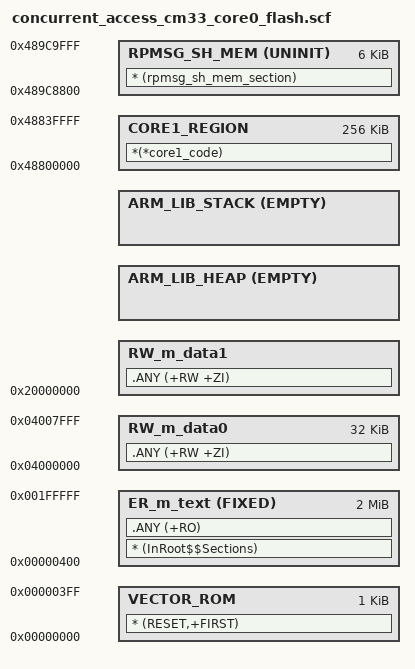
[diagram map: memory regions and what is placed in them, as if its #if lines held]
#! armcc -E
/*
** ###################################################################
**     Processors:          MCXW727AMFTA_cm33_core0
**                          MCXW727CMFTA_cm33_core0
**                          MCXW727DMFTA_cm33_core0
**
**     Compiler:            Keil ARM C/C++ Compiler
**     Reference manual:    Rev. 1, 2024-10-13
**     Version:             rev. 1.0, 2024-10-13
**     Build:               b241128
**
**     Abstract:
**         Linker file for the Keil ARM C/C++ Compiler
**
**     Copyright 2016 Freescale Semiconductor, Inc.
**     Copyright 2016-2025 NXP
**     SPDX-License-Identifier: BSD-3-Clause
**
**     http:                 www.nxp.com
**     mail:                 support@nxp.com
**
** ###################################################################
*/


/* Sizes */
#if (defined(__stack_size__))
  #define Stack_Size                   __stack_size__
#else
  #define Stack_Size                   0x0400
#endif

#if (defined(__heap_size__))
  #define Heap_Size                    __heap_size__
#else
  #define Heap_Size                    0x0400
#endif

#define  m_interrupts_start            0x00000000
#define  m_interrupts_size             0x00000400

#define  m_text_start                  0x00000400
#define  m_text_size                   0x001FFC00

#define  m_data0_start                  0x04000000
#define  m_data0_size                   0x00008000

#define  m_data1_start                  0x20000000
#define  m_data1_size                   0x00038000

#define m_core1_image_start            0x48800000
#define m_core1_image_size             0x00040000

/* On Main core we reserve the same address space as on NBU, but specifically
 * for making sure this section of memory does not get used by the main core.
 * So we just declare the memory area here for reference, but do not place any
 * output section there.
 */
#define m_nbu_s200_workarea_start      0x489C0000
#define m_nbu_s200_workarea_size       0x00001000

#if (defined(__use_shmem__))
  #define m_rpmsg_sh_mem_start         0x489C8800
  #define m_rpmsg_sh_mem_size          0x00001800
#endif

LR_m_text m_text_start m_text_size {   ; load region size_region
  ER_m_text m_text_start FIXED m_text_size { ; load address = execution address
    * (InRoot$$Sections)
    .ANY (+RO)
  }

#if (defined(__use_shmem__))
  RPMSG_SH_MEM m_rpmsg_sh_mem_start UNINIT m_rpmsg_sh_mem_size { ; Shared memory used by RPMSG
    * (rpmsg_sh_mem_section)
  }
#endif

  RW_m_data0 m_data0_start m_data0_size { ; RW data
    .ANY (+RW +ZI)
  }
  RW_m_data1 m_data1_start m_data1_size-Stack_Size-Heap_Size { ; RW data
    .ANY (+RW +ZI)
  }
  ARM_LIB_HEAP +0 EMPTY Heap_Size {    ; Heap region growing up
  }
  ARM_LIB_STACK m_data1_start+m_data1_size EMPTY -Stack_Size { ; Stack region growing down
  }
}

LR_m_interrupts m_interrupts_start m_interrupts_size {
  VECTOR_ROM m_interrupts_start m_interrupts_size { ; load address = execution address
    * (RESET,+FIRST)
  }
}

LR_CORE1_IMAGE m_core1_image_start {
  CORE1_REGION m_core1_image_start m_core1_image_size {
    *(*core1_code)
  }
}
